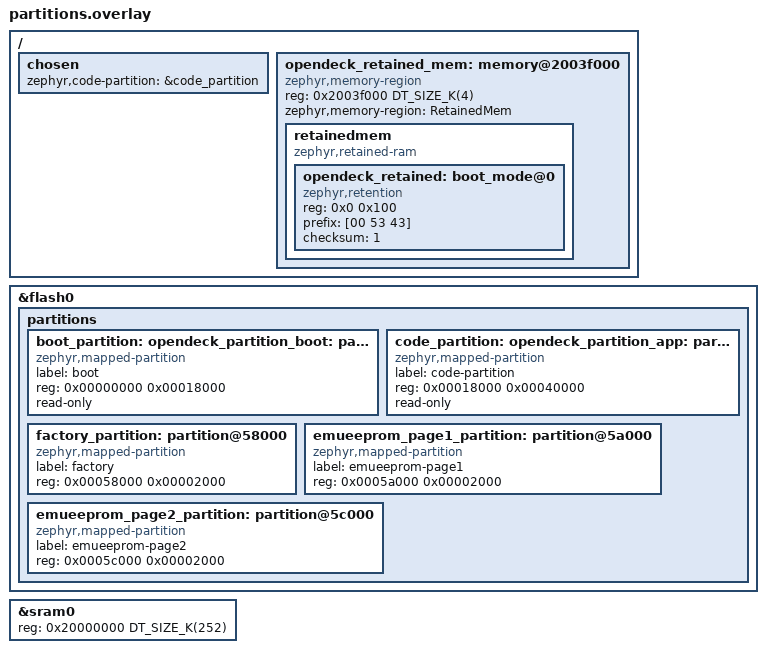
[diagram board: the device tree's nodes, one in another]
&flash0 {
    partitions {
        ranges;
        /delete-node/ boot_partition;
        /delete-node/ slot0_partition;
        /delete-node/ slot1_partition;
        /delete-node/ storage_partition;

        boot_partition: partition@0 {
            compatible = "zephyr,mapped-partition";
            label = "boot";
            reg = <0x00000000 0x00018000>;
            read-only;
        };

        code_partition: partition@18000 {
            compatible = "zephyr,mapped-partition";
            label = "code-partition";
            reg = <0x00018000 0x00040000>;
            read-only;
        };

        factory_partition: partition@58000 {
            compatible = "zephyr,mapped-partition";
            label = "factory";
            reg = <0x00058000 0x00002000>;
        };

        emueeprom_page1_partition: partition@5a000 {
            compatible = "zephyr,mapped-partition";
            label = "emueeprom-page1";
            reg = <0x0005a000 0x00002000>;
        };

        emueeprom_page2_partition: partition@5c000 {
            compatible = "zephyr,mapped-partition";
            label = "emueeprom-page2";
            reg = <0x0005c000 0x00002000>;
        };
    };
};

&sram0 {
    reg = <0x20000000 DT_SIZE_K(252)>;
    ranges = <0x0 0x20000000 DT_SIZE_K(252)>;
};

/ {
    chosen {
        zephyr,code-partition = &code_partition;
    };

    opendeck_retained_mem: memory@2003f000 {
        compatible = "zephyr,memory-region", "mmio-sram";
        reg = <0x2003f000 DT_SIZE_K(4)>;
        zephyr,memory-region = "RetainedMem";
        status = "okay";

        retainedmem {
            compatible = "zephyr,retained-ram";
            status = "okay";
            #address-cells = <1>;
            #size-cells = <1>;

            opendeck_retained: boot_mode@0 {
                compatible = "zephyr,retention";
                status = "okay";
                reg = <0x0 0x100>;
                prefix = [00 53 43];
                checksum = <1>;
            };
        };
    };
};

opendeck_partition_boot: &boot_partition {};

opendeck_partition_app: &code_partition {};
